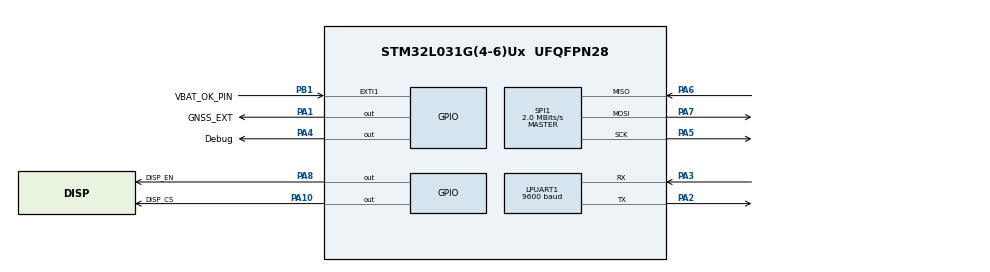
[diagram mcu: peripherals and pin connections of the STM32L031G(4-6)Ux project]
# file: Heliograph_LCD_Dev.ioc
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ADC.ClockPrescaler=ADC_CLOCK_ASYNC_DIV8
ADC.DiscontinuousConvMode=DISABLE
ADC.EOCSelection=ADC_EOC_SEQ_CONV
ADC.LowPowerAutoPowerOff=ENABLE
ADC.OversamplingMode=ENABLE
ADC.Ratio=ADC_OVERSAMPLING_RATIO_4
ADC.RightBitShift=ADC_RIGHTBITSHIFT_2
ADC.SamplingTime=ADC_SAMPLETIME_39CYCLES_5
ADC.TriggeredMode=ADC_TRIGGEREDMODE_SINGLE_TRIGGER
Dma.ADC.1.Direction=DMA_PERIPH_TO_MEMORY
Dma.ADC.1.Instance=DMA1_Channel1
Dma.ADC.1.MemDataAlignment=DMA_MDATAALIGN_HALFWORD
Dma.ADC.1.MemInc=DMA_MINC_ENABLE
Dma.ADC.1.Mode=DMA_NORMAL
Dma.ADC.1.PeriphDataAlignment=DMA_PDATAALIGN_HALFWORD
Dma.ADC.1.PeriphInc=DMA_PINC_DISABLE
Dma.ADC.1.Priority=DMA_PRIORITY_LOW
Dma.Request0=SPI1_TX
Dma.Request1=ADC
Dma.SPI1_TX.0.Direction=DMA_MEMORY_TO_PERIPH
Dma.SPI1_TX.0.Instance=DMA1_Channel3
Dma.SPI1_TX.0.MemDataAlignment=DMA_MDATAALIGN_BYTE
Dma.SPI1_TX.0.MemInc=DMA_MINC_ENABLE
Dma.SPI1_TX.0.Mode=DMA_NORMAL
Dma.SPI1_TX.0.PeriphDataAlignment=DMA_PDATAALIGN_BYTE
Dma.SPI1_TX.0.PeriphInc=DMA_PINC_DISABLE
Dma.SPI1_TX.0.Priority=DMA_PRIORITY_MEDIUM
IWDG.Prescaler=IWDG_PRESCALER_16
LPUART1.BaudRate=9600
LPUART1.DMADisableonRxErrorParam=UART_ADVFEATURE_DMA_ENABLEONRXERROR
LPUART1.OverrunDisableParam=UART_ADVFEATURE_OVERRUN_ENABLE
LPUART1.WordLength=UART_WORDLENGTH_8B
Mcu.Family=STM32L0
Mcu.Name=STM32L031G(4-6)Ux
Mcu.Package=UFQFPN28
NVIC.ADC1_COMP_IRQn=true\:0\:0\:false\:false\:true\:true\:true\:true
NVIC.DMA1_Channel1_IRQn=true\:0\:0\:true\:false\:true\:false\:true\:true
NVIC.DMA1_Channel2_3_IRQn=true\:2\:0\:true\:false\:true\:false\:true\:true
NVIC.EXTI0_1_IRQn=true\:0\:0\:false\:false\:true\:true\:true\:true
NVIC.LPUART1_IRQn=true\:1\:0\:true\:false\:true\:true\:false\:true
NVIC.RTC_IRQn=true\:0\:0\:false\:false\:true\:true\:true\:true
PA1.GPIO_Label=GNSS_EXT
PA1.Signal=GPIO_Output
PA10.GPIO_Label=DISP_CS
PA10.Signal=GPIO_Output
PA13.Mode=Serial_Wire
PA13.Signal=SYS_SWDIO
PA14.Mode=Serial_Wire
PA14.Signal=SYS_SWCLK
PA2.Mode=Asynchronous
PA2.Signal=LPUART1_TX
PA3.Mode=Asynchronous
PA3.Signal=LPUART1_RX
PA4.GPIO_Label=Debug
PA4.Signal=GPIO_Output
PA5.Mode=Full_Duplex_Master
PA5.Signal=SPI1_SCK
PA6.Mode=Full_Duplex_Master
PA6.Signal=SPI1_MISO
PA7.Mode=Full_Duplex_Master
PA7.Signal=SPI1_MOSI
PA8.GPIO_Label=DISP_EN
PA8.Signal=GPIO_Output
PB1.GPIO_Label=VBAT_OK_PIN
PB1.GPIO_ModeDefaultEXTI=GPIO_MODE_IT_RISING_FALLING
PB1.Signal=GPXTI1
PC14-OSC32_IN.Mode=LSE-External-Oscillator
PC14-OSC32_IN.Signal=RCC_OSC32_IN
PC15-OSC32_OUT.Mode=LSE-External-Oscillator
PC15-OSC32_OUT.Signal=RCC_OSC32_OUT
ProjectManager.HeapSize=0x200
ProjectManager.StackSize=0x400
ProjectManager.TargetToolchain=STM32CubeIDE
RCC.AHBFreq_Value=16000000
RCC.APB1Freq_Value=16000000
RCC.APB1TimFreq_Value=16000000
RCC.APB2Freq_Value=16000000
RCC.APB2TimFreq_Value=16000000
RCC.HCLKFreq_Value=16000000
RCC.HSE_VALUE=8000000
RCC.HSI16_VALUE=16000000
RCC.HSI_VALUE=16000000
RCC.LSE_Drive_Capability=RCC_LSEDRIVE_MEDIUMHIGH
RCC.LptimClockSelection=RCC_LPTIM1CLKSOURCE_LSE
RCC.Lpuart1ClockSelection=RCC_LPUART1CLKSOURCE_LSE
RCC.MSI_VALUE=2097000
RCC.PLLMUL=RCC_PLLMUL_4
RCC.PREFETCH_ENABLE=0
RCC.PWR_Regulator_Voltage_Scale=PWR_REGULATOR_VOLTAGE_SCALE1
RCC.RTCClockSelection=RCC_RTCCLKSOURCE_LSE
RCC.RTCClockSelectionVirtual=RCC_RTCCLKSOURCE_LSE
RCC.SYSCLKFreq_VALUE=16000000
RCC.SYSCLKSource=RCC_SYSCLKSOURCE_HSI
RCC.VCOOutputFreq_Value=64000000
RCC.VDD_VALUE=3
RTC.WakeUpCounter-WakeUp=2047
SPI1.BaudRatePrescaler=SPI_BAUDRATEPRESCALER_8
SPI1.CalculateBaudRate=2.0 MBits/s
SPI1.Direction=SPI_DIRECTION_2LINES
SPI1.FirstBit=SPI_FIRSTBIT_LSB
SPI1.Mode=SPI_MODE_MASTER
SPI1.VirtualType=VM_MASTER
VP_ADC_TempSens_Input.Mode=IN-TempSens
VP_ADC_Vref_Input.Mode=IN-Vrefint
VP_IWDG_VS_IWDG.Mode=IWDG_Activate
VP_RTC_VS_RTC_Activate.Mode=RTC_Enabled
VP_RTC_VS_RTC_WakeUp_intern.Mode=WakeUp
board=custom

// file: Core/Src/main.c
/* USER CODE BEGIN Header */
/**
 ******************************************************************************
 * @file           : main.c
 * @brief          : Main program body
 ******************************************************************************
 * @attention
 *
 * Copyright (c) 2022 STMicroelectronics.
 * All rights reserved.
 *
 * This software is licensed under terms that can be found in the LICENSE file
 * in the root directory of this software component.
 * If no LICENSE file comes with this software, it is provided AS-IS.
 *
 ******************************************************************************
 */
/* USER CODE END Header */
#include "main.h"

/* USER CODE BEGIN Includes */

#include "myApp.h"
/* USER CODE END Includes */

 ADC_HandleTypeDef hadc;
DMA_HandleTypeDef hdma_adc;

IWDG_HandleTypeDef hiwdg;

RTC_HandleTypeDef hrtc;

SPI_HandleTypeDef hspi1;
DMA_HandleTypeDef hdma_spi1_tx;

void SystemClock_Config(void);
static void MX_GPIO_Init(void);
static void MX_LPUART1_UART_Init(void);
static void MX_DMA_Init(void);
static void MX_SPI1_Init(void);
static void MX_RTC_Init(void);
static void MX_ADC_Init(void);
static void MX_IWDG_Init(void);

int main(void)
{

  /* MCU Configuration--------------------------------------------------------*/

  /* Reset of all peripherals, Initializes the Flash interface and the Systick. */
  HAL_Init();

  /* Configure the system clock */
  SystemClock_Config();

  /* Initialize all configured peripherals */
  MX_GPIO_Init();
  MX_LPUART1_UART_Init();
  MX_DMA_Init();
  MX_SPI1_Init();
  MX_RTC_Init();
  MX_ADC_Init();
  MX_IWDG_Init();
  /* USER CODE BEGIN 2 */

	myApp_init();

  /* USER CODE END 2 */

  /* Infinite loop */
  /* USER CODE BEGIN WHILE */
	while (1) {

		myApp_loop();

    /* USER CODE END WHILE */

	}
}

void SystemClock_Config(void)
{
  LL_FLASH_SetLatency(LL_FLASH_LATENCY_0);
  while(LL_FLASH_GetLatency()!= LL_FLASH_LATENCY_0)
  {
  }
  LL_PWR_SetRegulVoltageScaling(LL_PWR_REGU_VOLTAGE_SCALE1);
  LL_RCC_HSI_Enable();

   /* Wait till HSI is ready */
  while(LL_RCC_HSI_IsReady() != 1)
  {

  }
  LL_RCC_HSI_SetCalibTrimming(16);
  LL_RCC_LSI_Enable();

   /* Wait till LSI is ready */
  while(LL_RCC_LSI_IsReady() != 1)
  {

  }
  LL_PWR_EnableBkUpAccess();
  if(LL_RCC_GetRTCClockSource() != LL_RCC_RTC_CLKSOURCE_LSE)
  {
    LL_RCC_ForceBackupDomainReset();
    LL_RCC_ReleaseBackupDomainReset();
  }
  LL_RCC_LSE_SetDriveCapability(LL_RCC_LSEDRIVE_MEDIUMHIGH);
  LL_RCC_LSE_Enable();

   /* Wait till LSE is ready */
  while(LL_RCC_LSE_IsReady() != 1)
  {

  }
  if(LL_RCC_GetRTCClockSource() != LL_RCC_RTC_CLKSOURCE_LSE)
  {
    LL_RCC_SetRTCClockSource(LL_RCC_RTC_CLKSOURCE_LSE);
  }
  LL_RCC_EnableRTC();
  LL_RCC_SetAHBPrescaler(LL_RCC_SYSCLK_DIV_1);
  LL_RCC_SetAPB1Prescaler(LL_RCC_APB1_DIV_1);
  LL_RCC_SetAPB2Prescaler(LL_RCC_APB2_DIV_1);
  LL_RCC_SetSysClkSource(LL_RCC_SYS_CLKSOURCE_HSI);

   /* Wait till System clock is ready */
  while(LL_RCC_GetSysClkSource() != LL_RCC_SYS_CLKSOURCE_STATUS_HSI)
  {

  }
  LL_SetSystemCoreClock(16000000);

   /* Update the time base */
  if (HAL_InitTick (TICK_INT_PRIORITY) != HAL_OK)
  {
    Error_Handler();
  }
  LL_RCC_SetLPUARTClockSource(LL_RCC_LPUART1_CLKSOURCE_LSE);
}

static void MX_ADC_Init(void)
{

  ADC_ChannelConfTypeDef sConfig = {0};

  /** Configure the global features of the ADC (Clock, Resolution, Data Alignment and number of conversion)
  */
  hadc.Instance = ADC1;
  hadc.Init.OversamplingMode = ENABLE;
  hadc.Init.Oversample.Ratio = ADC_OVERSAMPLING_RATIO_4;
  hadc.Init.Oversample.RightBitShift = ADC_RIGHTBITSHIFT_2;
  hadc.Init.Oversample.TriggeredMode = ADC_TRIGGEREDMODE_SINGLE_TRIGGER;
  hadc.Init.ClockPrescaler = ADC_CLOCK_ASYNC_DIV8;
  hadc.Init.Resolution = ADC_RESOLUTION_12B;
  hadc.Init.SamplingTime = ADC_SAMPLETIME_39CYCLES_5;
  hadc.Init.ScanConvMode = ADC_SCAN_DIRECTION_FORWARD;
  hadc.Init.DataAlign = ADC_DATAALIGN_RIGHT;
  hadc.Init.ContinuousConvMode = DISABLE;
  hadc.Init.DiscontinuousConvMode = DISABLE;
  hadc.Init.ExternalTrigConvEdge = ADC_EXTERNALTRIGCONVEDGE_NONE;
  hadc.Init.ExternalTrigConv = ADC_SOFTWARE_START;
  hadc.Init.DMAContinuousRequests = DISABLE;
  hadc.Init.EOCSelection = ADC_EOC_SEQ_CONV;
  hadc.Init.Overrun = ADC_OVR_DATA_PRESERVED;
  hadc.Init.LowPowerAutoWait = DISABLE;
  hadc.Init.LowPowerFrequencyMode = ENABLE;
  hadc.Init.LowPowerAutoPowerOff = ENABLE;
  if (HAL_ADC_Init(&hadc) != HAL_OK)
  {
    Error_Handler();
  }

  /** Configure for the selected ADC regular channel to be converted.
  */
  sConfig.Channel = ADC_CHANNEL_TEMPSENSOR;
  sConfig.Rank = ADC_RANK_CHANNEL_NUMBER;
  if (HAL_ADC_ConfigChannel(&hadc, &sConfig) != HAL_OK)
  {
    Error_Handler();
  }

  /** Configure for the selected ADC regular channel to be converted.
  */
  sConfig.Channel = ADC_CHANNEL_VREFINT;
  if (HAL_ADC_ConfigChannel(&hadc, &sConfig) != HAL_OK)
  {
    Error_Handler();
  }

}

static void MX_IWDG_Init(void)
{

  hiwdg.Instance = IWDG;
  hiwdg.Init.Prescaler = IWDG_PRESCALER_16;
  hiwdg.Init.Window = 4095;
  hiwdg.Init.Reload = 4095;
  if (HAL_IWDG_Init(&hiwdg) != HAL_OK)
  {
    Error_Handler();
  }

}

static void MX_LPUART1_UART_Init(void)
{

  LL_LPUART_InitTypeDef LPUART_InitStruct = {0};

  LL_GPIO_InitTypeDef GPIO_InitStruct = {0};

  /* Peripheral clock enable */
  LL_APB1_GRP1_EnableClock(LL_APB1_GRP1_PERIPH_LPUART1);

  LL_IOP_GRP1_EnableClock(LL_IOP_GRP1_PERIPH_GPIOA);
  /**LPUART1 GPIO Configuration
  PA2   ------> LPUART1_TX
  PA3   ------> LPUART1_RX
  */
  GPIO_InitStruct.Pin = LL_GPIO_PIN_2;
  GPIO_InitStruct.Mode = LL_GPIO_MODE_ALTERNATE;
  GPIO_InitStruct.Speed = LL_GPIO_SPEED_FREQ_VERY_HIGH;
  GPIO_InitStruct.OutputType = LL_GPIO_OUTPUT_PUSHPULL;
  GPIO_InitStruct.Pull = LL_GPIO_PULL_NO;
  GPIO_InitStruct.Alternate = LL_GPIO_AF_6;
  LL_GPIO_Init(GPIOA, &GPIO_InitStruct);

  GPIO_InitStruct.Pin = LL_GPIO_PIN_3;
  GPIO_InitStruct.Mode = LL_GPIO_MODE_ALTERNATE;
  GPIO_InitStruct.Speed = LL_GPIO_SPEED_FREQ_VERY_HIGH;
  GPIO_InitStruct.OutputType = LL_GPIO_OUTPUT_PUSHPULL;
  GPIO_InitStruct.Pull = LL_GPIO_PULL_NO;
  GPIO_InitStruct.Alternate = LL_GPIO_AF_6;
  LL_GPIO_Init(GPIOA, &GPIO_InitStruct);

  /* LPUART1 interrupt Init */
  NVIC_SetPriority(LPUART1_IRQn, 1);
  NVIC_EnableIRQ(LPUART1_IRQn);

  LPUART_InitStruct.BaudRate = 9600;
  LPUART_InitStruct.DataWidth = LL_LPUART_DATAWIDTH_8B;
  LPUART_InitStruct.StopBits = LL_LPUART_STOPBITS_1;
  LPUART_InitStruct.Parity = LL_LPUART_PARITY_NONE;
  LPUART_InitStruct.TransferDirection = LL_LPUART_DIRECTION_TX_RX;
  LPUART_InitStruct.HardwareFlowControl = LL_LPUART_HWCONTROL_NONE;
  LL_LPUART_Init(LPUART1, &LPUART_InitStruct);

}

static void MX_RTC_Init(void)
{

  /** Initialize RTC Only
  */
  hrtc.Instance = RTC;
  hrtc.Init.HourFormat = RTC_HOURFORMAT_24;
  hrtc.Init.AsynchPrediv = 127;
  hrtc.Init.SynchPrediv = 255;
  hrtc.Init.OutPut = RTC_OUTPUT_DISABLE;
  hrtc.Init.OutPutRemap = RTC_OUTPUT_REMAP_NONE;
  hrtc.Init.OutPutPolarity = RTC_OUTPUT_POLARITY_HIGH;
  hrtc.Init.OutPutType = RTC_OUTPUT_TYPE_OPENDRAIN;
  if (HAL_RTC_Init(&hrtc) != HAL_OK)
  {
    Error_Handler();
  }

  /** Enable the WakeUp
  */
  if (HAL_RTCEx_SetWakeUpTimer_IT(&hrtc, 2047, RTC_WAKEUPCLOCK_RTCCLK_DIV16) != HAL_OK)
  {
    Error_Handler();
  }

}

static void MX_SPI1_Init(void)
{

  /* SPI1 parameter configuration*/
  hspi1.Instance = SPI1;
  hspi1.Init.Mode = SPI_MODE_MASTER;
  hspi1.Init.Direction = SPI_DIRECTION_2LINES;
  hspi1.Init.DataSize = SPI_DATASIZE_8BIT;
  hspi1.Init.CLKPolarity = SPI_POLARITY_LOW;
  hspi1.Init.CLKPhase = SPI_PHASE_1EDGE;
  hspi1.Init.NSS = SPI_NSS_SOFT;
  hspi1.Init.BaudRatePrescaler = SPI_BAUDRATEPRESCALER_8;
  hspi1.Init.FirstBit = SPI_FIRSTBIT_LSB;
  hspi1.Init.TIMode = SPI_TIMODE_DISABLE;
  hspi1.Init.CRCCalculation = SPI_CRCCALCULATION_DISABLE;
  hspi1.Init.CRCPolynomial = 7;
  if (HAL_SPI_Init(&hspi1) != HAL_OK)
  {
    Error_Handler();
  }

}

static void MX_DMA_Init(void)
{

  /* DMA controller clock enable */
  __HAL_RCC_DMA1_CLK_ENABLE();

  /* DMA interrupt init */
  /* DMA1_Channel1_IRQn interrupt configuration */
  HAL_NVIC_SetPriority(DMA1_Channel1_IRQn, 0, 0);
  HAL_NVIC_EnableIRQ(DMA1_Channel1_IRQn);
  /* DMA1_Channel2_3_IRQn interrupt configuration */
  HAL_NVIC_SetPriority(DMA1_Channel2_3_IRQn, 2, 0);
  HAL_NVIC_EnableIRQ(DMA1_Channel2_3_IRQn);

}

static void MX_GPIO_Init(void)
{
  GPIO_InitTypeDef GPIO_InitStruct = {0};

  /* GPIO Ports Clock Enable */
  __HAL_RCC_GPIOC_CLK_ENABLE();
  __HAL_RCC_GPIOA_CLK_ENABLE();
  __HAL_RCC_GPIOB_CLK_ENABLE();

  /*Configure GPIO pin Output Level */
  HAL_GPIO_WritePin(GPIOA, GNSS_EXT_Pin|Debug_Pin|DISP_EN_Pin|DISP_CS_Pin, GPIO_PIN_RESET);

  /*Configure GPIO pins : PA0 PA9 PA15 */
  GPIO_InitStruct.Pin = GPIO_PIN_0|GPIO_PIN_9|GPIO_PIN_15;
  GPIO_InitStruct.Mode = GPIO_MODE_ANALOG;
  GPIO_InitStruct.Pull = GPIO_NOPULL;
  HAL_GPIO_Init(GPIOA, &GPIO_InitStruct);

  /*Configure GPIO pins : GNSS_EXT_Pin Debug_Pin DISP_EN_Pin DISP_CS_Pin */
  GPIO_InitStruct.Pin = GNSS_EXT_Pin|Debug_Pin|DISP_EN_Pin|DISP_CS_Pin;
  GPIO_InitStruct.Mode = GPIO_MODE_OUTPUT_PP;
  GPIO_InitStruct.Pull = GPIO_NOPULL;
  GPIO_InitStruct.Speed = GPIO_SPEED_FREQ_LOW;
  HAL_GPIO_Init(GPIOA, &GPIO_InitStruct);

  /*Configure GPIO pins : PB0 PB3 PB6 PB7 */
  GPIO_InitStruct.Pin = GPIO_PIN_0|GPIO_PIN_3|GPIO_PIN_6|GPIO_PIN_7;
  GPIO_InitStruct.Mode = GPIO_MODE_ANALOG;
  GPIO_InitStruct.Pull = GPIO_NOPULL;
  HAL_GPIO_Init(GPIOB, &GPIO_InitStruct);

  /*Configure GPIO pin : VBAT_OK_PIN_Pin */
  GPIO_InitStruct.Pin = VBAT_OK_PIN_Pin;
  GPIO_InitStruct.Mode = GPIO_MODE_IT_RISING_FALLING;
  GPIO_InitStruct.Pull = GPIO_NOPULL;
  HAL_GPIO_Init(VBAT_OK_PIN_GPIO_Port, &GPIO_InitStruct);

  /* EXTI interrupt init*/
  HAL_NVIC_SetPriority(EXTI0_1_IRQn, 0, 0);
  HAL_NVIC_EnableIRQ(EXTI0_1_IRQn);

}

void Error_Handler(void)
{
	__disable_irq();
	while (1) {
	}
}
